# STM32U575 register map
File version: 1.4
CPU: CM33 r0p1, little endian, MPU, FPU, 4 interrupt priority bits
Registers are 32-bit, read-write, reset 0x0 unless marked. A register's access mark holds for its fields unless they carry their own. Offsets are from the block's base; [hi:lo] are bit positions; {n}, {i} and the like mark numbered series.

## GTZC1_MPCBB3
Base 0x40033400
Same registers: SEC_GTZC1_MPCBB3 0x50033400
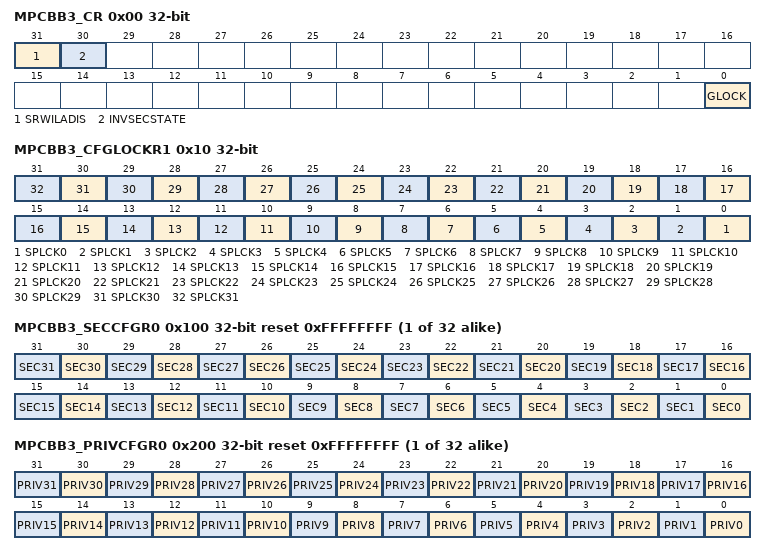
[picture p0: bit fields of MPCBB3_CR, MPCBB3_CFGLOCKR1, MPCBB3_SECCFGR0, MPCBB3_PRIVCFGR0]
0x00 MPCBB3_CR — MPCBB control register
  [31] SRWILADIS — secure read/write illegal access disable
  [30] INVSECSTATE — SRAMx clocks security state
  [0] GLOCK — lock the control register of the MPCBB until next reset
0x10 MPCBB3_CFGLOCKR1 — GTZC1 SRAMz MPCBB configuration lock register
  [n] SPLCK{n} (n=0..31)
{0x100+4i} MPCBB3_SECCFGR{i} reset 0xFFFFFFFF (i=0..31) — MPCBBx security configuration for super-block x register
  [n] SEC{n} (n=0..31)
{0x200+4i} MPCBB3_PRIVCFGR{i} reset 0xFFFFFFFF (i=0..31) — MPCBB privileged configuration for super-block x register
  [n] PRIV{n} (n=0..31)

## GTZC2_MPCBB4
Base 0x46023800
Same registers: SEC_GTZC2_MPCBB4 0x56023800
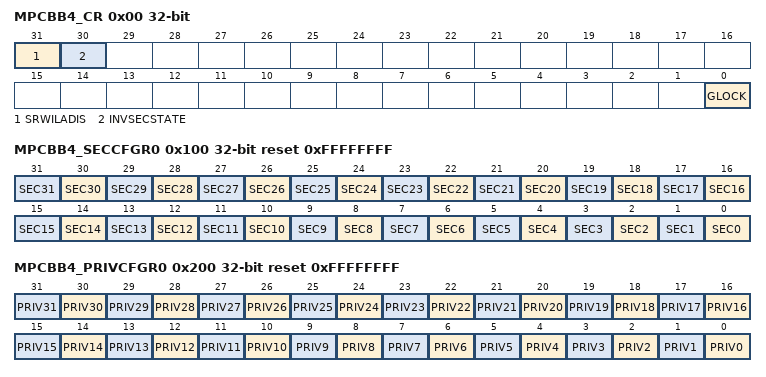
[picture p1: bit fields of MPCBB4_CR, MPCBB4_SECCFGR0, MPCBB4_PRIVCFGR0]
0x00 MPCBB4_CR — MPCBB control register
  [31] SRWILADIS — secure read/write illegal access disable
  [30] INVSECSTATE — SRAMx clocks security state
  [0] GLOCK — lock the control register of the MPCBB until next reset
0x10 MPCBB4_CFGLOCK — GTZC2 SRAM4 MPCBB configuration lock register
  [0] SPLCK0 — Security/privilege configuration lock for super-block 0
0x100 MPCBB4_SECCFGR0 reset 0xFFFFFFFF — MPCBB security configuration for super-block 0 register
  [n] SEC{n} (n=0..31)
0x200 MPCBB4_PRIVCFGR0 reset 0xFFFFFFFF — MPCBB privileged configuration for super-block 0 register
  [n] PRIV{n} (n=0..31)

## GTZC2_TZSC
Base 0x46023000
Same registers: SEC_GTZC2_TZSC 0x56023000
0x00 TZSC_CR — TZSC control register
  [0] LCK — lock the configuration of GTZC1_TZSC_SECCFGRx and GTZC1_TZSC_PRIVCFGRx registers until next reset
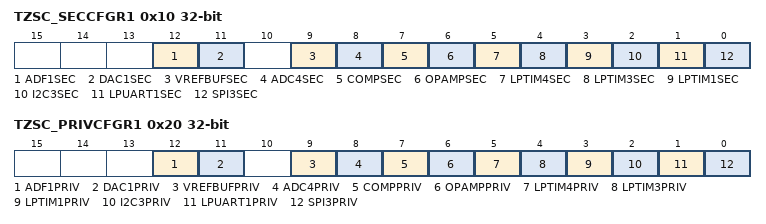
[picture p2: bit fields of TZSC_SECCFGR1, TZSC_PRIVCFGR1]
0x10 TZSC_SECCFGR1 — TZSC secure configuration register 1
  [12] ADF1SEC — secure access mode for ADF1
  [11] DAC1SEC — secure access mode for DAC1
  [9] VREFBUFSEC — secure access mode for VREFBUF
  [8] ADC4SEC — secure access mode for ADC4
  [7] COMPSEC — secure access mode for COMP
  [6] OPAMPSEC — secure access mode for OPAMP
  [5] LPTIM4SEC — secure access mode for LPTIM4
  [4] LPTIM3SEC — secure access mode for LPTIM3
  [3] LPTIM1SEC — secure access mode for LPTIM1
  [2] I2C3SEC — secure access mode for I2C3
  [1] LPUART1SEC — secure access mode for LPUART1
  [0] SPI3SEC — secure access mode for SPI3
0x20 TZSC_PRIVCFGR1 — TZSC privilege configuration register 1
  [12] ADF1PRIV — privileged access mode for ADF1
  [11] DAC1PRIV — privileged access mode for DAC1
  [9] VREFBUFPRIV — privileged access mode for VREFBUF
  [8] ADC4PRIV — privileged access mode for ADC4
  [7] COMPPRIV — privileged access mode for COMP
  [6] OPAMPPRIV — privileged access mode for OPAMP
  [5] LPTIM4PRIV — privileged access mode for LPTIM4
  [4] LPTIM3PRIV — privileged access mode for LPTIM3
  [3] LPTIM1PRIV — privileged access mode for LPTIM1
  [2] I2C3PRIV — privileged access mode for I2C3
  [1] LPUART1PRIV — privileged access mode for LPUART1
  [0] SPI3PRIV — privileged access mode for SPI3

## TIM6 — General-purpose-timers
Base 0x40001000
Same registers: TIM7 0x40001400, SEC_TIM6 0x50001000, SEC_TIM7 0x50001400
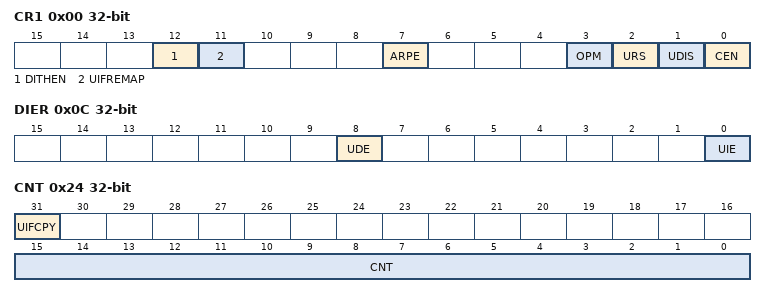
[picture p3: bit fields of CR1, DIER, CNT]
0x00 CR1 — control register 1
  [12] DITHEN — Dithering Enable
  [11] UIFREMAP — UIF status bit remapping
  [7] ARPE — Auto-reload preload enable
  [3] OPM — One-pulse mode
  [2] URS — Update request source
  [1] UDIS — Update disable
  [0] CEN — Counter enable
0x04 CR2 — control register 2
  [6:4] MMS — Master mode selection
0x0C DIER — DMA/Interrupt enable register
  [8] UDE, [0] UIE
0x10 SR — status register
  [0] UIF
0x14 EGR wo — event generation register
  [0] UG
0x24 CNT — counter
  [31] UIFCPY, [15:0] CNT
0x28 PSC — prescaler
  [15:0] PSC
0x2C ARR reset 0xFFFF — auto-reload register
  [18:0] ARR
